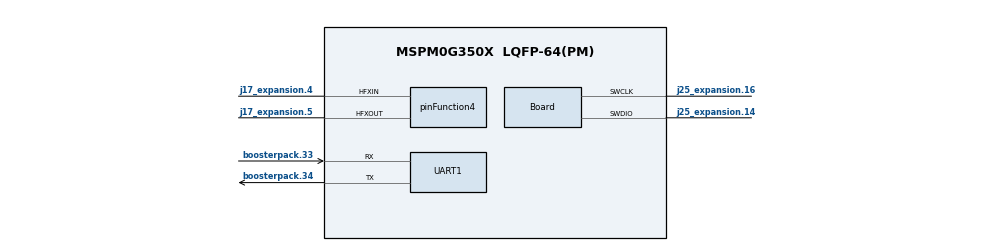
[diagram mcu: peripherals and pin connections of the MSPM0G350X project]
/**
 * @cliArgs --board "/ti/boards/LP_MSPM0G3507" --device "MSPM0G350X" --part "Default" --package "LQFP-64(PM)" --product "mspm0_sdk@2.01.00.03"
 * @versions {"tool":"1.21.1+3772"}
 */

/**
 * Import the modules used in this configuration.
 */
const SYSCTL        = scripting.addModule("/ti/driverlib/SYSCTL");
const UART          = scripting.addModule("/ti/driverlib/UART", {}, false);
const UART1         = UART.addInstance();
const ProjectConfig = scripting.addModule("/ti/project_config/ProjectConfig");

/**
 * Write custom configuration values to the imported modules.
 */
const divider6       = system.clockTree["PLL_CLK2X_DIV"];
divider6.divideValue = 3;

const divider7       = system.clockTree["PLL_PDIV"];
divider7.divideValue = 2;

const divider9       = system.clockTree["UDIV"];
divider9.divideValue = 2;

const multiplier2         = system.clockTree["PLL_QDIV"];
multiplier2.multiplyValue = 5;

const mux4       = system.clockTree["EXHFMUX"];
mux4.inputSelect = "EXHFMUX_XTAL";

const mux8       = system.clockTree["HSCLKMUX"];
mux8.inputSelect = "HSCLKMUX_SYSPLL2X";

const mux12       = system.clockTree["SYSPLLMUX"];
mux12.inputSelect = "zSYSPLLMUX_HFCLK";

const oscillator2           = system.clockTree["SYSOSC"];
oscillator2.enableSYSOSCFCL = true;

const pinFunction4                        = system.clockTree["HFXT"];
pinFunction4.enable                       = true;
pinFunction4.inputFreq                    = 48;
pinFunction4.HFCLKMonitor                 = true;
pinFunction4.HFXTStartup                  = 10;
pinFunction4.peripheral.$assign           = "SYSCTL";
pinFunction4.peripheral.hfxInPin.$assign  = "j17_expansion.4";
pinFunction4.peripheral.hfxOutPin.$assign = "j17_expansion.5";

SYSCTL.HFCLKSource           = "HFXT";
SYSCTL.HFCLK_Freq            = 25000000;
SYSCTL.enableSYSOSCFCL       = true;
SYSCTL.SYSPLL_Pdiv           = 4;
SYSCTL.SYSPLL_Qdiv           = 5;
SYSCTL.SYSPLL_CLK2XEn        = true;
SYSCTL.clockTreeEn           = true;
SYSCTL.validateClkStatus     = true;
SYSCTL.forceDefaultClkConfig = true;

const Board                       = scripting.addModule("/ti/driverlib/Board", {}, false);
Board.peripheral.$assign          = "DEBUGSS";
Board.peripheral.swclkPin.$assign = "j25_expansion.16";
Board.peripheral.swdioPin.$assign = "j25_expansion.14";

UART1.ovsRate                          = "8";
UART1.rxFifoThreshold                  = "DL_UART_RX_FIFO_LEVEL_ONE_ENTRY";
UART1.interruptPriority                = "1";
UART1.enabledInterrupts                = ["RX"];
UART1.targetBaudRate                   = 1000000;
UART1.$name                            = "UART_TEST";
UART1.peripheral.$assign               = "UART0";
UART1.peripheral.rxPin.$assign         = "boosterpack.33";
UART1.peripheral.txPin.$assign         = "boosterpack.34";
UART1.txPinConfig.$name                = "ti_driverlib_gpio_GPIOPinGeneric0";
UART1.txPinConfig.direction            = scripting.forceWrite("OUTPUT");
UART1.txPinConfig.hideOutputInversion  = scripting.forceWrite(false);
UART1.txPinConfig.onlyInternalResistor = scripting.forceWrite(false);
UART1.txPinConfig.passedPeripheralType = scripting.forceWrite("Digital");
UART1.txPinConfig.enableConfig         = true;
UART1.rxPinConfig.$name                = "ti_driverlib_gpio_GPIOPinGeneric1";
UART1.rxPinConfig.hideOutputInversion  = scripting.forceWrite(false);
UART1.rxPinConfig.onlyInternalResistor = scripting.forceWrite(false);
UART1.rxPinConfig.passedPeripheralType = scripting.forceWrite("Digital");

ProjectConfig.genDisable         = true;
ProjectConfig.migrationCondition = true;
scripting.suppress("Project Configuration File generation is disabled for this project\\. SysConfig Project Migration is not currently supported for this project\\.", ProjectConfig);
